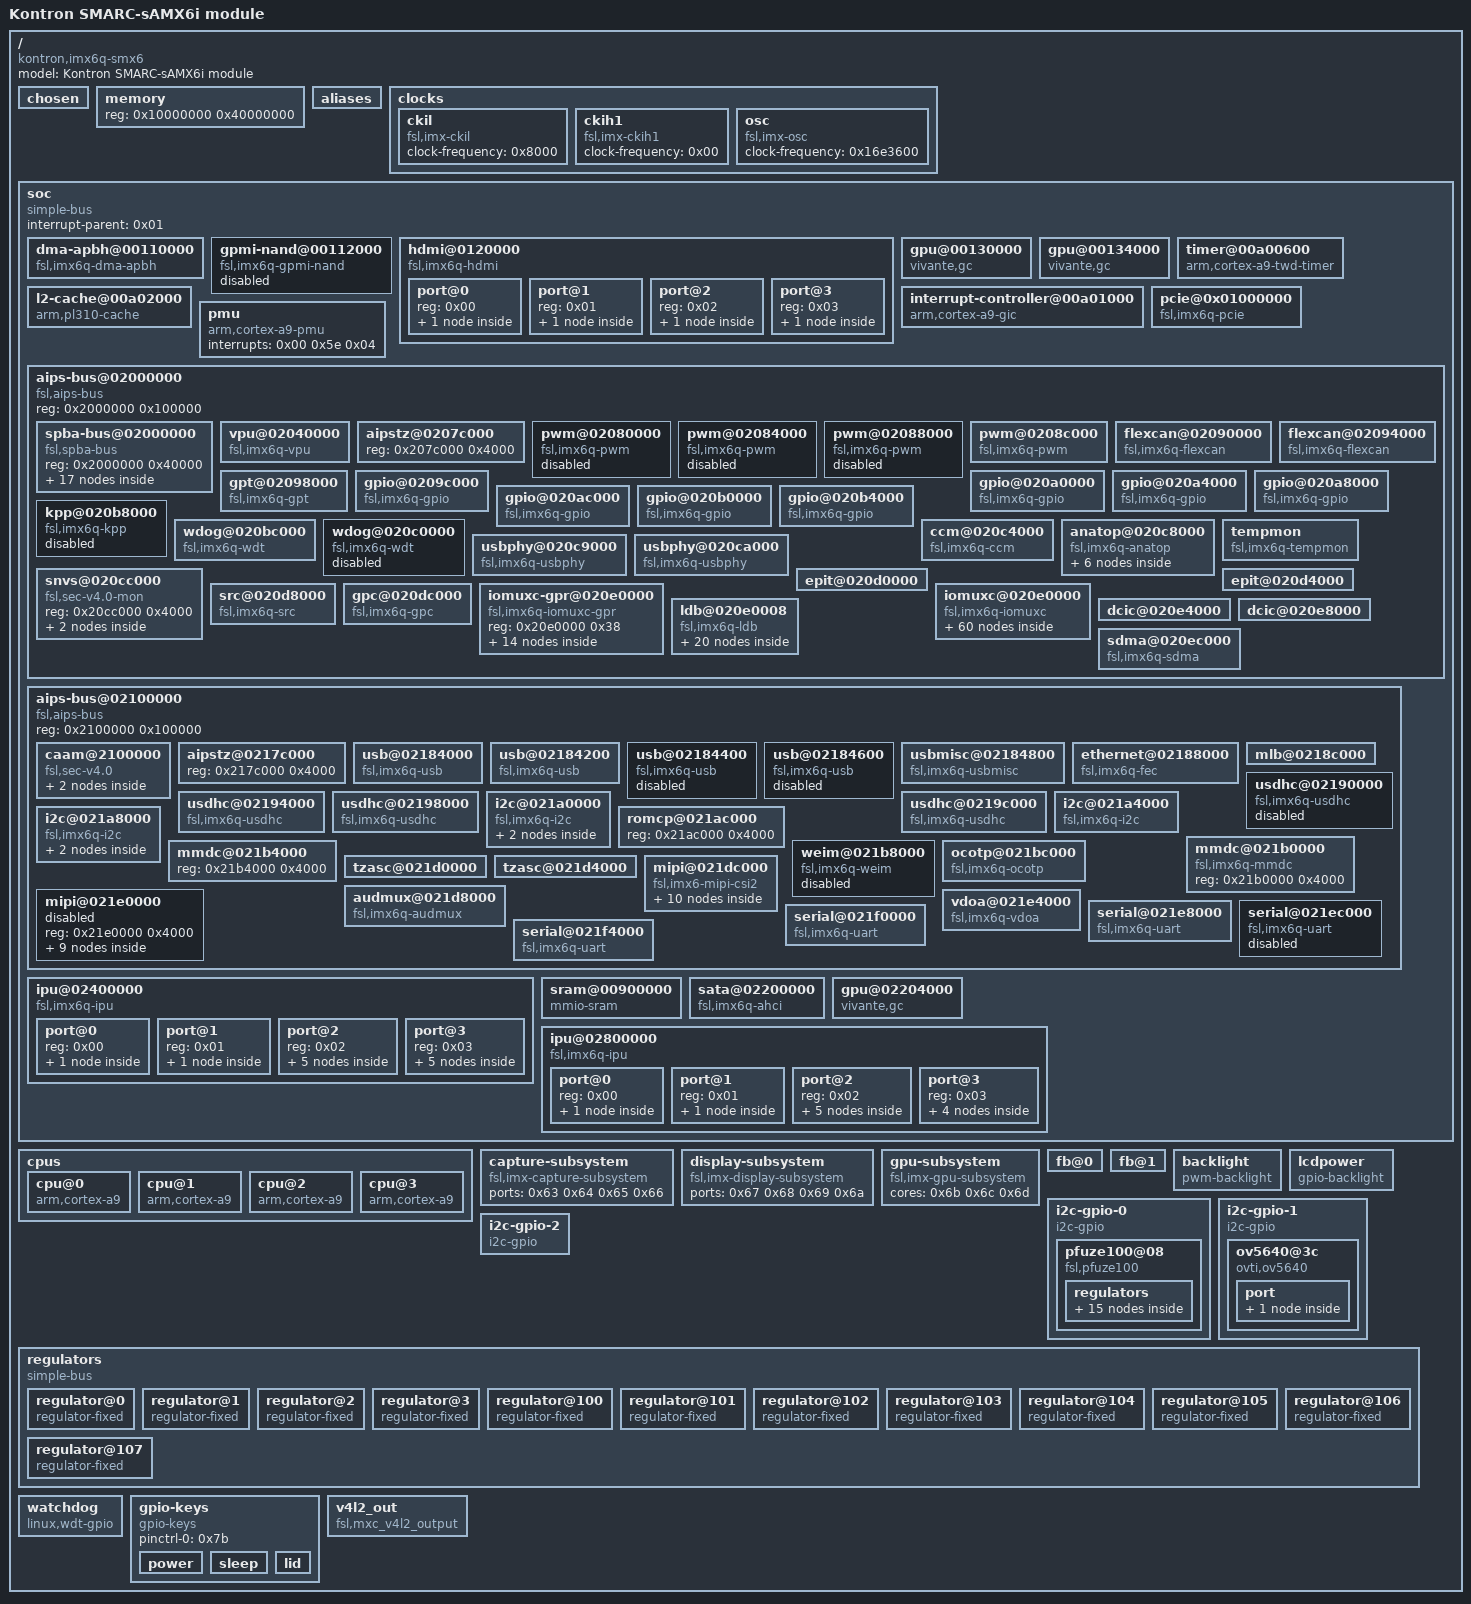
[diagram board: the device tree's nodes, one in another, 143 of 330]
/dts-v1/;

/ {
	#address-cells = <0x01>;
	#size-cells = <0x01>;
	model = "Kontron SMARC-sAMX6i module";
	compatible = "kontron,imx6q-smx6\0fsl,imx6q";

	chosen {
	};

	memory {
		device_type = "memory";
		reg = <0x10000000 0x40000000>;
	};

	aliases {
		ethernet0 = "/soc/aips-bus@02100000/ethernet@02188000";
		can0 = "/soc/aips-bus@02000000/flexcan@02090000";
		can1 = "/soc/aips-bus@02000000/flexcan@02094000";
		gpio0 = "/soc/aips-bus@02000000/gpio@0209c000";
		gpio1 = "/soc/aips-bus@02000000/gpio@020a0000";
		gpio2 = "/soc/aips-bus@02000000/gpio@020a4000";
		gpio3 = "/soc/aips-bus@02000000/gpio@020a8000";
		gpio4 = "/soc/aips-bus@02000000/gpio@020ac000";
		gpio5 = "/soc/aips-bus@02000000/gpio@020b0000";
		gpio6 = "/soc/aips-bus@02000000/gpio@020b4000";
		i2c0 = "/soc/aips-bus@02100000/i2c@021a0000";
		i2c1 = "/soc/aips-bus@02100000/i2c@021a4000";
		i2c2 = "/soc/aips-bus@02100000/i2c@021a8000";
		ipu0 = "/soc/ipu@02400000";
		mmc0 = "/soc/aips-bus@02100000/usdhc@02190000";
		mmc1 = "/soc/aips-bus@02100000/usdhc@02194000";
		mmc2 = "/soc/aips-bus@02100000/usdhc@02198000";
		mmc3 = "/soc/aips-bus@02100000/usdhc@0219c000";
		serial0 = "/soc/aips-bus@02000000/spba-bus@02000000/serial@02020000";
		serial1 = "/soc/aips-bus@02100000/serial@021e8000";
		serial2 = "/soc/aips-bus@02100000/serial@021ec000";
		serial3 = "/soc/aips-bus@02100000/serial@021f0000";
		serial4 = "/soc/aips-bus@02100000/serial@021f4000";
		spi0 = "/soc/aips-bus@02000000/spba-bus@02000000/ecspi@02014000";
		spi1 = "/soc/aips-bus@02000000/spba-bus@02000000/ecspi@0200c000";
		spi2 = "/soc/aips-bus@02000000/spba-bus@02000000/ecspi@02010000";
		spi3 = "/soc/aips-bus@02000000/spba-bus@02000000/ecspi@02014000";
		usbphy0 = "/soc/aips-bus@02000000/usbphy@020c9000";
		usbphy1 = "/soc/aips-bus@02000000/usbphy@020ca000";
		ipu1 = "/soc/ipu@02800000";
		spi4 = "/soc/aips-bus@02000000/spba-bus@02000000/ecspi@02018000";
		i2c3 = "/i2c-gpio-0";
		i2c4 = "/i2c-gpio-1";
		i2c5 = "/i2c-gpio-2";
	};

	clocks {
		#address-cells = <0x01>;
		#size-cells = <0x00>;

		ckil {
			compatible = "fsl,imx-ckil\0fixed-clock";
			#clock-cells = <0x00>;
			clock-frequency = <0x8000>;
		};

		ckih1 {
			compatible = "fsl,imx-ckih1\0fixed-clock";
			#clock-cells = <0x00>;
			clock-frequency = <0x00>;
		};

		osc {
			compatible = "fsl,imx-osc\0fixed-clock";
			#clock-cells = <0x00>;
			clock-frequency = <0x16e3600>;
		};
	};

	soc {
		#address-cells = <0x01>;
		#size-cells = <0x01>;
		compatible = "simple-bus";
		interrupt-parent = <0x01>;
		ranges;

		dma-apbh@00110000 {
			compatible = "fsl,imx6q-dma-apbh\0fsl,imx28-dma-apbh";
			reg = <0x110000 0x2000>;
			interrupts = <0x00 0x0d 0x04 0x00 0x0d 0x04 0x00 0x0d 0x04 0x00 0x0d 0x04>;
			interrupt-names = "gpmi0\0gpmi1\0gpmi2\0gpmi3";
			#dma-cells = <0x01>;
			dma-channels = <0x04>;
			clocks = <0x02 0x6a>;
			linux,phandle = <0x03>;
			phandle = <0x03>;
		};

		gpmi-nand@00112000 {
			compatible = "fsl,imx6q-gpmi-nand";
			#address-cells = <0x01>;
			#size-cells = <0x01>;
			reg = <0x112000 0x2000 0x114000 0x2000>;
			reg-names = "gpmi-nand\0bch";
			interrupts = <0x00 0x0f 0x04>;
			interrupt-names = "bch";
			clocks = <0x02 0x98 0x02 0x99 0x02 0x97 0x02 0x96 0x02 0x95>;
			clock-names = "gpmi_io\0gpmi_apb\0gpmi_bch\0gpmi_bch_apb\0per1_bch";
			dmas = <0x03 0x00>;
			dma-names = "rx-tx";
			status = "disabled";
		};

		hdmi@0120000 {
			#address-cells = <0x01>;
			#size-cells = <0x00>;
			reg = <0x120000 0x9000>;
			interrupts = <0x00 0x73 0x04>;
			gpr = <0x04>;
			clocks = <0x02 0x7b 0x02 0x7c>;
			clock-names = "iahb\0isfr";
			status = "okay";
			compatible = "fsl,imx6q-hdmi";
			ddc-i2c-bus = <0x05>;
			ipu_id = <0x01>;
			disp_id = <0x00>;

			port@0 {
				reg = <0x00>;

				endpoint {
					remote-endpoint = <0x06>;
					linux,phandle = <0x4e>;
					phandle = <0x4e>;
				};
			};

			port@1 {
				reg = <0x01>;

				endpoint {
					remote-endpoint = <0x07>;
					linux,phandle = <0x52>;
					phandle = <0x52>;
				};
			};

			port@2 {
				reg = <0x02>;

				endpoint {
					remote-endpoint = <0x08>;
					linux,phandle = <0x58>;
					phandle = <0x58>;
				};
			};

			port@3 {
				reg = <0x03>;

				endpoint {
					remote-endpoint = <0x09>;
					linux,phandle = <0x5c>;
					phandle = <0x5c>;
				};
			};
		};

		gpu@00130000 {
			compatible = "vivante,gc";
			reg = <0x130000 0x4000>;
			interrupts = <0x00 0x09 0x04>;
			clocks = <0x02 0x1b 0x02 0x7a 0x02 0x4a>;
			clock-names = "bus\0core\0shader";
			power-domains = <0x01 0x01>;
			linux,phandle = <0x6c>;
			phandle = <0x6c>;
		};

		gpu@00134000 {
			compatible = "vivante,gc";
			reg = <0x134000 0x4000>;
			interrupts = <0x00 0x0a 0x04>;
			clocks = <0x02 0x1a 0x02 0x79>;
			clock-names = "bus\0core";
			power-domains = <0x01 0x01>;
			linux,phandle = <0x6b>;
			phandle = <0x6b>;
		};

		timer@00a00600 {
			compatible = "arm,cortex-a9-twd-timer";
			reg = <0xa00600 0x20>;
			interrupts = <0x01 0x0d 0xf01>;
			interrupt-parent = <0x0a>;
			clocks = <0x02 0x0f>;
		};

		interrupt-controller@00a01000 {
			compatible = "arm,cortex-a9-gic";
			#interrupt-cells = <0x03>;
			interrupt-controller;
			reg = <0xa01000 0x1000 0xa00100 0x100>;
			interrupt-parent = <0x0a>;
			linux,phandle = <0x0a>;
			phandle = <0x0a>;
		};

		l2-cache@00a02000 {
			compatible = "arm,pl310-cache";
			reg = <0xa02000 0x1000>;
			interrupts = <0x00 0x5c 0x04>;
			cache-unified;
			cache-level = <0x02>;
			arm,tag-latency = <0x04 0x02 0x03>;
			arm,data-latency = <0x04 0x02 0x03>;
			arm,shared-override;
			linux,phandle = <0x60>;
			phandle = <0x60>;
		};

		pcie@0x01000000 {
			compatible = "fsl,imx6q-pcie\0snps,dw-pcie";
			reg = <0x1ffc000 0x4000 0x1f00000 0x80000>;
			reg-names = "dbi\0config";
			#address-cells = <0x03>;
			#size-cells = <0x02>;
			device_type = "pci";
			ranges = <0x81000000 0x00 0x00 0x1f80000 0x00 0x10000 0x82000000 0x00 0x1000000 0x1000000 0x00 0xf00000>;
			num-lanes = <0x01>;
			interrupts = <0x00 0x78 0x04>;
			interrupt-names = "msi";
			#interrupt-cells = <0x01>;
			interrupt-map-mask = <0x00 0x00 0x00 0x07>;
			interrupt-map = <0x00 0x00 0x00 0x01 0x01 0x00 0x7b 0x04 0x00 0x00 0x00 0x02 0x01 0x00 0x7a 0x04 0x00 0x00 0x00 0x03 0x01 0x00 0x79 0x04 0x00 0x00 0x00 0x04 0x01 0x00 0x78 0x04>;
			clocks = <0x02 0x90 0x02 0xce 0x02 0xbd>;
			clock-names = "pcie\0pcie_bus\0pcie_phy";
			status = "okay";
			fsl,max-link-speed = <0x01>;
			wake-up-gpio = <0x0b 0x12 0x00>;
			reset-gpio = <0x0c 0x00 0x01 0x0d 0x0d 0x01 0x0d 0x0e 0x01 0x0d 0x0f 0x01>;
			pinctrl-names = "default";
			pinctrl-0 = <0x0e>;
		};

		pmu {
			compatible = "arm,cortex-a9-pmu";
			interrupts = <0x00 0x5e 0x04>;
		};

		aips-bus@02000000 {
			compatible = "fsl,aips-bus\0simple-bus";
			#address-cells = <0x01>;
			#size-cells = <0x01>;
			reg = <0x2000000 0x100000>;
			ranges;

			spba-bus@02000000 {
				compatible = "fsl,spba-bus\0simple-bus";
				#address-cells = <0x01>;
				#size-cells = <0x01>;
				reg = <0x2000000 0x40000>;
				ranges;

				spdif@02004000 {
					compatible = "fsl,imx35-spdif";
					reg = <0x2004000 0x4000>;
					interrupts = <0x00 0x34 0x04>;
					dmas = <0x0f 0x0e 0x12 0x00 0x0f 0x0f 0x12 0x00>;
					dma-names = "rx\0tx";
					clocks = <0x02 0xf4 0x02 0x03 0x02 0xc5 0x02 0x6b 0x02 0x00 0x02 0x76 0x02 0x3e 0x02 0x00 0x02 0x00 0x02 0x9c>;
					clock-names = "core\0rxtx0\0rxtx1\0rxtx2\0rxtx3\0rxtx4\0rxtx5\0rxtx6\0rxtx7\0spba";
					status = "disabled";
				};

				ecspi@02008000 {
					#address-cells = <0x01>;
					#size-cells = <0x00>;
					compatible = "fsl,imx6q-ecspi\0fsl,imx51-ecspi";
					reg = <0x2008000 0x4000>;
					interrupts = <0x00 0x1f 0x04>;
					clocks = <0x02 0x70 0x02 0x70>;
					clock-names = "ipg\0per";
					dmas = <0x0f 0x03 0x08 0x01 0x0f 0x04 0x08 0x02>;
					dma-names = "rx\0tx";
					status = "disabled";
				};

				ecspi@0200c000 {
					#address-cells = <0x01>;
					#size-cells = <0x00>;
					compatible = "fsl,imx6q-ecspi\0fsl,imx51-ecspi";
					reg = <0x200c000 0x4000>;
					interrupts = <0x00 0x20 0x04>;
					clocks = <0x02 0x71 0x02 0x71>;
					clock-names = "ipg\0per";
					dmas = <0x0f 0x05 0x08 0x01 0x0f 0x06 0x08 0x02>;
					dma-names = "rx\0tx";
					status = "okay";
					pinctrl-names = "default";
					pinctrl-0 = <0x10>;
					fsl,spi-num-chipselects = <0x02>;
					cs-gpios = <0x0c 0x1a 0x00 0x0c 0x1b 0x00>;
				};

				ecspi@02010000 {
					#address-cells = <0x01>;
					#size-cells = <0x00>;
					compatible = "fsl,imx6q-ecspi\0fsl,imx51-ecspi";
					reg = <0x2010000 0x4000>;
					interrupts = <0x00 0x21 0x04>;
					clocks = <0x02 0x72 0x02 0x72>;
					clock-names = "ipg\0per";
					dmas = <0x0f 0x07 0x08 0x01 0x0f 0x08 0x08 0x02>;
					dma-names = "rx\0tx";
					status = "disabled";
				};

				ecspi@02014000 {
					#address-cells = <0x01>;
					#size-cells = <0x00>;
					compatible = "fsl,imx6q-ecspi\0fsl,imx51-ecspi";
					reg = <0x2014000 0x4000>;
					interrupts = <0x00 0x22 0x04>;
					clocks = <0x02 0x73 0x02 0x73>;
					clock-names = "ipg\0per";
					dmas = <0x0f 0x09 0x08 0x01 0x0f 0x0a 0x08 0x02>;
					dma-names = "rx\0tx";
					status = "okay";
					pinctrl-names = "default";
					pinctrl-0 = <0x11>;
					fsl,spi-num-chipselects = <0x03>;
					cs-gpios = <0x0d 0x18 0x00 0x0d 0x1d 0x00 0x0d 0x19 0x00>;

					spi-nor@0 {
						#address-cells = <0x01>;
						#size-cells = <0x01>;
						compatible = "winbond,w25q16dw\0jedec,spi-nor";
						spi-max-frequency = <0x1312d00>;
						reg = <0x00>;

						partition@0 {
							label = "bootloader";
							reg = <0x00 0xc0000>;
							read-only;
						};

						partition@c0000 {
							label = "environment";
							reg = <0xc0000 0x10000>;
						};

						partition@d0000 {
							label = "user";
							reg = <0xd0000 0x00>;
						};
					};
				};

				serial@02020000 {
					compatible = "fsl,imx6q-uart\0fsl,imx21-uart";
					reg = <0x2020000 0x4000>;
					interrupts = <0x00 0x1a 0x04>;
					clocks = <0x02 0xa0 0x02 0xa1>;
					clock-names = "ipg\0per";
					dmas = <0x0f 0x19 0x04 0x00 0x0f 0x1a 0x04 0x00>;
					dma-names = "rx\0tx";
					status = "okay";
					pinctrl-names = "default";
					pinctrl-0 = <0x12>;
					fsl,uart-has-rtscts;
				};

				esai@02024000 {
					#sound-dai-cells = <0x00>;
					compatible = "fsl,imx35-esai";
					reg = <0x2024000 0x4000>;
					interrupts = <0x00 0x33 0x04>;
					clocks = <0x02 0xd0 0x02 0xd1 0x02 0x76 0x02 0xd0 0x02 0x9c>;
					clock-names = "core\0mem\0extal\0fsys\0spba";
					dmas = <0x0f 0x17 0x15 0x00 0x0f 0x18 0x15 0x00>;
					dma-names = "rx\0tx";
					status = "disabled";
				};

				ssi@02028000 {
					#sound-dai-cells = <0x00>;
					compatible = "fsl,imx6q-ssi\0fsl,imx51-ssi";
					reg = <0x2028000 0x4000>;
					interrupts = <0x00 0x2e 0x04>;
					clocks = <0x02 0xb2 0x02 0x9d>;
					clock-names = "ipg\0baud";
					dmas = <0x0f 0x25 0x01 0x00 0x0f 0x26 0x01 0x00>;
					dma-names = "rx\0tx";
					fsl,fifo-depth = <0x0f>;
					status = "okay";
					linux,phandle = <0x7c>;
					phandle = <0x7c>;
				};

				ssi@0202c000 {
					#sound-dai-cells = <0x00>;
					compatible = "fsl,imx6q-ssi\0fsl,imx51-ssi";
					reg = <0x202c000 0x4000>;
					interrupts = <0x00 0x2f 0x04>;
					clocks = <0x02 0xb3 0x02 0x9e>;
					clock-names = "ipg\0baud";
					dmas = <0x0f 0x29 0x01 0x00 0x0f 0x2a 0x01 0x00>;
					dma-names = "rx\0tx";
					fsl,fifo-depth = <0x0f>;
					status = "disabled";
				};

				ssi@02030000 {
					#sound-dai-cells = <0x00>;
					compatible = "fsl,imx6q-ssi\0fsl,imx51-ssi";
					reg = <0x2030000 0x4000>;
					interrupts = <0x00 0x30 0x04>;
					clocks = <0x02 0xb4 0x02 0x9f>;
					clock-names = "ipg\0baud";
					dmas = <0x0f 0x2d 0x01 0x00 0x0f 0x2e 0x01 0x00>;
					dma-names = "rx\0tx";
					fsl,fifo-depth = <0x0f>;
					status = "disabled";
				};

				asrc@02034000 {
					compatible = "fsl,imx53-asrc";
					reg = <0x2034000 0x4000>;
					interrupts = <0x00 0x32 0x04>;
					clocks = <0x02 0xd2 0x02 0xd3 0x02 0x00 0x02 0x00 0x02 0x00 0x02 0x00 0x02 0x00 0x02 0x00 0x02 0x00 0x02 0x00 0x02 0x00 0x02 0x00 0x02 0x00 0x02 0x00 0x02 0x00 0x02 0x6b 0x02 0x00 0x02 0x00 0x02 0x9c>;
					clock-names = "mem\0ipg\0asrck_0\0asrck_1\0asrck_2\0asrck_3\0asrck_4\0asrck_5\0asrck_6\0asrck_7\0asrck_8\0asrck_9\0asrck_a\0asrck_b\0asrck_c\0asrck_d\0asrck_e\0asrck_f\0spba";
					dmas = <0x0f 0x11 0x17 0x01 0x0f 0x12 0x17 0x01 0x0f 0x13 0x17 0x01 0x0f 0x14 0x17 0x01 0x0f 0x15 0x17 0x01 0x0f 0x16 0x17 0x01>;
					dma-names = "rxa\0rxb\0rxc\0txa\0txb\0txc";
					fsl,asrc-rate = <0xbb80>;
					fsl,asrc-width = <0x10>;
					status = "okay";
				};

				spba@0203c000 {
					reg = <0x203c000 0x4000>;
				};

				ecspi@02018000 {
					#address-cells = <0x01>;
					#size-cells = <0x00>;
					compatible = "fsl,imx6q-ecspi\0fsl,imx51-ecspi";
					reg = <0x2018000 0x4000>;
					interrupts = <0x00 0x23 0x04>;
					clocks = <0x02 0x74 0x02 0x74>;
					clock-names = "ipg\0per";
					dmas = <0x0f 0x0b 0x07 0x01 0x0f 0x0c 0x07 0x02>;
					dma-names = "rx\0tx";
					status = "disabled";
				};
			};

			vpu@02040000 {
				compatible = "fsl,imx6q-vpu\0cnm,coda960";
				reg = <0x2040000 0x3c000>;
				interrupts = <0x00 0x0c 0x04 0x00 0x03 0x04>;
				interrupt-names = "bit\0jpeg";
				clocks = <0x02 0xa8 0x02 0x8c>;
				clock-names = "per\0ahb";
				power-domains = <0x01 0x01>;
				resets = <0x13 0x01>;
				iram = <0x14>;
			};

			aipstz@0207c000 {
				reg = <0x207c000 0x4000>;
			};

			pwm@02080000 {
				#pwm-cells = <0x02>;
				compatible = "fsl,imx6q-pwm\0fsl,imx27-pwm";
				reg = <0x2080000 0x4000>;
				interrupts = <0x00 0x53 0x04>;
				clocks = <0x02 0x3e 0x02 0x91>;
				clock-names = "ipg\0per";
				status = "disabled";
			};

			pwm@02084000 {
				#pwm-cells = <0x02>;
				compatible = "fsl,imx6q-pwm\0fsl,imx27-pwm";
				reg = <0x2084000 0x4000>;
				interrupts = <0x00 0x54 0x04>;
				clocks = <0x02 0x3e 0x02 0x92>;
				clock-names = "ipg\0per";
				status = "disabled";
			};

			pwm@02088000 {
				#pwm-cells = <0x02>;
				compatible = "fsl,imx6q-pwm\0fsl,imx27-pwm";
				reg = <0x2088000 0x4000>;
				interrupts = <0x00 0x55 0x04>;
				clocks = <0x02 0x3e 0x02 0x93>;
				clock-names = "ipg\0per";
				status = "disabled";
			};

			pwm@0208c000 {
				#pwm-cells = <0x02>;
				compatible = "fsl,imx6q-pwm\0fsl,imx27-pwm";
				reg = <0x208c000 0x4000>;
				interrupts = <0x00 0x56 0x04>;
				clocks = <0x02 0x3e 0x02 0x94>;
				clock-names = "ipg\0per";
				status = "okay";
				pinctrl-names = "default";
				pinctrl-0 = <0x15>;
				linux,phandle = <0x6f>;
				phandle = <0x6f>;
			};

			flexcan@02090000 {
				compatible = "fsl,imx6q-flexcan";
				reg = <0x2090000 0x4000>;
				interrupts = <0x00 0x6e 0x04>;
				clocks = <0x02 0x6c 0x02 0x6d>;
				clock-names = "ipg\0per";
				status = "okay";
				pinctrl-names = "default";
				pinctrl-0 = <0x16>;
				xceiver-supply = <0x17>;
			};

			flexcan@02094000 {
				compatible = "fsl,imx6q-flexcan";
				reg = <0x2094000 0x4000>;
				interrupts = <0x00 0x6f 0x04>;
				clocks = <0x02 0x6e 0x02 0x6f>;
				clock-names = "ipg\0per";
				status = "okay";
				pinctrl-names = "default";
				pinctrl-0 = <0x18>;
				xceiver-supply = <0x19>;
			};

			gpt@02098000 {
				compatible = "fsl,imx6q-gpt\0fsl,imx31-gpt";
				reg = <0x2098000 0x4000>;
				interrupts = <0x00 0x37 0x04>;
				clocks = <0x02 0x77 0x02 0x78 0x02 0xed>;
				clock-names = "ipg\0per\0osc_per";
			};

			gpio@0209c000 {
				compatible = "fsl,imx6q-gpio\0fsl,imx35-gpio";
				reg = <0x209c000 0x4000>;
				interrupts = <0x00 0x42 0x04 0x00 0x43 0x04>;
				gpio-controller;
				#gpio-cells = <0x02>;
				interrupt-controller;
				#interrupt-cells = <0x02>;
				gpio-ranges = <0x1a 0x00 0x88 0x02 0x1a 0x02 0x8d 0x01 0x1a 0x03 0x8b 0x01 0x1a 0x04 0x8e 0x02 0x1a 0x06 0x8c 0x01 0x1a 0x07 0x90 0x02 0x1a 0x09 0x8a 0x01 0x1a 0x0a 0xd5 0x03 0x1a 0x0d 0x14 0x01 0x1a 0x0e 0x13 0x01 0x1a 0x0f 0x15 0x01 0x1a 0x10 0xd0 0x01 0x1a 0x11 0xcf 0x01 0x1a 0x12 0xd2 0x03 0x1a 0x15 0xd1 0x01 0x1a 0x16 0x74 0x0a>;
				linux,phandle = <0x35>;
				phandle = <0x35>;
			};

			gpio@020a0000 {
				compatible = "fsl,imx6q-gpio\0fsl,imx35-gpio";
				reg = <0x20a0000 0x4000>;
				interrupts = <0x00 0x44 0x04 0x00 0x45 0x04>;
				gpio-controller;
				#gpio-cells = <0x02>;
				interrupt-controller;
				#interrupt-cells = <0x02>;
				gpio-ranges = <0x1a 0x00 0xbf 0x10 0x1a 0x10 0x37 0x0e 0x1a 0x1e 0x23 0x01 0x1a 0x1f 0x2c 0x01>;
				linux,phandle = <0x0c>;
				phandle = <0x0c>;
			};

			gpio@020a4000 {
				compatible = "fsl,imx6q-gpio\0fsl,imx35-gpio";
				reg = <0x20a4000 0x4000>;
				interrupts = <0x00 0x46 0x04 0x00 0x47 0x04>;
				gpio-controller;
				#gpio-cells = <0x02>;
				interrupt-controller;
				#interrupt-cells = <0x02>;
				gpio-ranges = <0x1a 0x00 0x45 0x10 0x1a 0x10 0x24 0x08 0x1a 0x18 0x2d 0x08>;
				linux,phandle = <0x0d>;
				phandle = <0x0d>;
			};

			gpio@020a8000 {
				compatible = "fsl,imx6q-gpio\0fsl,imx35-gpio";
				reg = <0x20a8000 0x4000>;
				interrupts = <0x00 0x48 0x04 0x00 0x49 0x04>;
				gpio-controller;
				#gpio-cells = <0x02>;
				interrupt-controller;
				#interrupt-cells = <0x02>;
				gpio-ranges = <0x1a 0x05 0x95 0x01 0x1a 0x06 0x7e 0x0a 0x1a 0x10 0x57 0x10>;
				linux,phandle = <0x76>;
				phandle = <0x76>;
			};

			gpio@020ac000 {
				compatible = "fsl,imx6q-gpio\0fsl,imx35-gpio";
				reg = <0x20ac000 0x4000>;
				interrupts = <0x00 0x4a 0x04 0x00 0x4b 0x04>;
				gpio-controller;
				#gpio-cells = <0x02>;
				interrupt-controller;
				#interrupt-cells = <0x02>;
				gpio-ranges = <0x1a 0x00 0x55 0x01 0x1a 0x02 0x22 0x01 0x1a 0x04 0x35 0x01 0x1a 0x05 0x67 0x0d 0x1a 0x12 0x96 0x0e>;
				linux,phandle = <0x7a>;
				phandle = <0x7a>;
			};

			gpio@020b0000 {
				compatible = "fsl,imx6q-gpio\0fsl,imx35-gpio";
				reg = <0x20b0000 0x4000>;
				interrupts = <0x00 0x4c 0x04 0x00 0x4d 0x04>;
				gpio-controller;
				#gpio-cells = <0x02>;
				interrupt-controller;
				#interrupt-cells = <0x02>;
				gpio-ranges = <0x1a 0x00 0xa4 0x06 0x1a 0x06 0x36 0x01 0x1a 0x07 0xb5 0x05 0x1a 0x0e 0xba 0x03 0x1a 0x11 0xaa 0x02 0x1a 0x13 0x16 0x0c 0x1a 0x1f 0x56 0x01>;
				linux,phandle = <0x0b>;
				phandle = <0x0b>;
			};

			gpio@020b4000 {
				compatible = "fsl,imx6q-gpio\0fsl,imx35-gpio";
				reg = <0x20b4000 0x4000>;
				interrupts = <0x00 0x4e 0x04 0x00 0x4f 0x04>;
				gpio-controller;
				#gpio-cells = <0x02>;
				interrupt-controller;
				#interrupt-cells = <0x02>;
				gpio-ranges = <0x1a 0x00 0xac 0x09 0x1a 0x09 0xbd 0x02 0x1a 0x0b 0x92 0x03>;
				linux,phandle = <0x74>;
				phandle = <0x74>;
			};

			kpp@020b8000 {
				compatible = "fsl,imx6q-kpp\0fsl,imx21-kpp";
				reg = <0x20b8000 0x4000>;
				interrupts = <0x00 0x52 0x04>;
				clocks = <0x02 0x3e>;
				status = "disabled";
			};

			wdog@020bc000 {
				compatible = "fsl,imx6q-wdt\0fsl,imx21-wdt";
				reg = <0x20bc000 0x4000>;
				interrupts = <0x00 0x50 0x04>;
				clocks = <0x02 0x00>;
			};

			wdog@020c0000 {
				compatible = "fsl,imx6q-wdt\0fsl,imx21-wdt";
				reg = <0x20c0000 0x4000>;
				interrupts = <0x00 0x51 0x04>;
				clocks = <0x02 0x00>;
				status = "disabled";
			};

			ccm@020c4000 {
				compatible = "fsl,imx6q-ccm";
				reg = <0x20c4000 0x4000>;
				interrupts = <0x00 0x57 0x04 0x00 0x58 0x04>;
				#clock-cells = <0x01>;
				linux,phandle = <0x02>;
				phandle = <0x02>;
			};

			anatop@020c8000 {
				compatible = "fsl,imx6q-anatop\0syscon\0simple-bus";
				reg = <0x20c8000 0x1000>;
				interrupts = <0x00 0x31 0x04 0x00 0x36 0x04 0x00 0x7f 0x04>;
				linux,phandle = <0x1b>;
				phandle = <0x1b>;

				regulator-1p1 {
					compatible = "fsl,anatop-regulator";
					regulator-name = "vdd1p1";
					regulator-min-microvolt = "\0\f5";
					regulator-max-microvolt = <0x14fb18>;
					regulator-always-on;
					anatop-reg-offset = <0x110>;
					anatop-vol-bit-shift = <0x08>;
					anatop-vol-bit-width = <0x05>;
					anatop-min-bit-val = <0x04>;
					anatop-min-voltage = "\0\f5";
					anatop-max-voltage = <0x14fb18>;
				};

				regulator-3p0 {
					compatible = "fsl,anatop-regulator";
					regulator-name = "vdd3p0";
					regulator-min-microvolt = <0x2ab980>;
					regulator-max-microvolt = <0x3010b0>;
					regulator-always-on;
					anatop-reg-offset = <0x120>;
					anatop-vol-bit-shift = <0x08>;
					anatop-vol-bit-width = <0x05>;
					anatop-min-bit-val = <0x00>;
					anatop-min-voltage = <0x280de8>;
					anatop-max-voltage = <0x33e140>;
				};

				regulator-2p5 {
					compatible = "fsl,anatop-regulator";
					regulator-name = "vdd2p5";
					regulator-min-microvolt = <0x1e8480>;
					regulator-max-microvolt = <0x29f630>;
					regulator-always-on;
					anatop-reg-offset = <0x130>;
					anatop-vol-bit-shift = <0x08>;
					anatop-vol-bit-width = <0x05>;
					anatop-min-bit-val = <0x00>;
					anatop-min-voltage = <0x1e8480>;
					anatop-max-voltage = <0x29f630>;
				};

				regulator-vddcore {
					compatible = "fsl,anatop-regulator";
					regulator-name = "vddarm";
					regulator-min-microvolt = <0xb1008>;
					regulator-max-microvolt = <0x162010>;
					regulator-always-on;
					anatop-reg-offset = <0x140>;
					anatop-vol-bit-shift = <0x00>;
					anatop-vol-bit-width = <0x05>;
					anatop-delay-reg-offset = <0x170>;
					anatop-delay-bit-shift = <0x18>;
					anatop-delay-bit-width = <0x02>;
					anatop-min-bit-val = <0x01>;
					anatop-min-voltage = <0xb1008>;
					anatop-max-voltage = <0x162010>;
					linux,phandle = <0x61>;
					phandle = <0x61>;
				};

				regulator-vddpu {
					compatible = "fsl,anatop-regulator";
					regulator-name = "vddpu";
					regulator-min-microvolt = <0xb1008>;
					regulator-max-microvolt = <0x162010>;
					regulator-enable-ramp-delay = <0x96>;
					anatop-reg-offset = <0x140>;
					anatop-vol-bit-shift = <0x09>;
					anatop-vol-bit-width = <0x05>;
					anatop-delay-reg-offset = <0x170>;
					anatop-delay-bit-shift = <0x1a>;
					anatop-delay-bit-width = <0x02>;
					anatop-min-bit-val = <0x01>;
					anatop-min-voltage = <0xb1008>;
					anatop-max-voltage = <0x162010>;
					linux,phandle = <0x1e>;
					phandle = <0x1e>;
				};

				regulator-vddsoc {
					compatible = "fsl,anatop-regulator";
					regulator-name = "vddsoc";
					regulator-min-microvolt = <0xb1008>;
					regulator-max-microvolt = <0x162010>;
					regulator-always-on;
					anatop-reg-offset = <0x140>;
					anatop-vol-bit-shift = <0x12>;
					anatop-vol-bit-width = <0x05>;
					anatop-delay-reg-offset = <0x170>;
					anatop-delay-bit-shift = <0x1c>;
					anatop-delay-bit-width = <0x02>;
					anatop-min-bit-val = <0x01>;
					anatop-min-voltage = <0xb1008>;
					anatop-max-voltage = <0x162010>;
					linux,phandle = <0x62>;
					phandle = <0x62>;
				};
			};

			tempmon {
				compatible = "fsl,imx6q-tempmon";
				interrupts = <0x00 0x31 0x04>;
				fsl,tempmon = <0x1b>;
				fsl,tempmon-data = <0x1c>;
				clocks = <0x02 0xac>;
			};

			usbphy@020c9000 {
				compatible = "fsl,imx6q-usbphy\0fsl,imx23-usbphy";
				reg = <0x20c9000 0x1000>;
				interrupts = <0x00 0x2c 0x04>;
				clocks = <0x02 0xb6>;
				fsl,anatop = <0x1b>;
				linux,phandle = <0x2d>;
				phandle = <0x2d>;
			};

			usbphy@020ca000 {
				compatible = "fsl,imx6q-usbphy\0fsl,imx23-usbphy";
				reg = <0x20ca000 0x1000>;
				interrupts = <0x00 0x2d 0x04>;
				clocks = <0x02 0xb7>;
				fsl,anatop = <0x1b>;
				linux,phandle = <0x31>;
				phandle = <0x31>;
			};

			snvs@020cc000 {
				compatible = "fsl,sec-v4.0-mon\0syscon\0simple-mfd";
				reg = <0x20cc000 0x4000>;
				linux,phandle = <0x1d>;
				phandle = <0x1d>;

				snvs-rtc-lp {
					compatible = "fsl,sec-v4.0-mon-rtc-lp";
					regmap = <0x1d>;
					offset = <0x34>;
					interrupts = <0x00 0x13 0x04 0x00 0x14 0x04>;
				};

				snvs-poweroff {
					compatible = "syscon-poweroff";
					regmap = <0x1d>;
					offset = <0x38>;
					mask = <0x60>;
					status = "okay";
				};
			};

			epit@020d0000 {
				reg = <0x20d0000 0x4000>;
				interrupts = <0x00 0x38 0x04>;
			};

			epit@020d4000 {
				reg = <0x20d4000 0x4000>;
				interrupts = <0x00 0x39 0x04>;
			};

			src@020d8000 {
				compatible = "fsl,imx6q-src\0fsl,imx51-src";
				reg = <0x20d8000 0x4000>;
				interrupts = <0x00 0x5b 0x04 0x00 0x60 0x04>;
				#reset-cells = <0x01>;
				linux,phandle = <0x13>;
				phandle = <0x13>;
			};

			gpc@020dc000 {
				compatible = "fsl,imx6q-gpc";
				reg = <0x20dc000 0x4000>;
				interrupt-controller;
				#interrupt-cells = <0x03>;
				interrupts = <0x00 0x59 0x04 0x00 0x5a 0x04>;
				interrupt-parent = <0x0a>;
				pu-supply = <0x1e>;
				clocks = <0x02 0x7a 0x02 0x4a 0x02 0x79 0x02 0x1a 0x02 0x8f 0x02 0xa8>;
				#power-domain-cells = <0x01>;
				linux,phandle = <0x01>;
				phandle = <0x01>;
			};

			iomuxc-gpr@020e0000 {
				compatible = "fsl,imx6q-iomuxc-gpr\0syscon\0simple-mfd";
				reg = <0x20e0000 0x38>;
				#address-cells = <0x01>;
				#size-cells = <0x00>;
				linux,phandle = <0x04>;
				phandle = <0x04>;

				ipu1_csi0_mux@4 {
					compatible = "video-multiplexer";
					reg = <0x04>;
					bit-mask = <0x01>;
					bit-shift = <0x13>;
					#address-cells = <0x01>;
					#size-cells = <0x00>;
					status = "okay";

					port@0 {
						reg = <0x00>;

						endpoint {
							remote-endpoint = <0x1f>;
							linux,phandle = <0x40>;
							phandle = <0x40>;
						};
					};

					port@1 {
						reg = <0x01>;

						endpoint {
						};
					};

					port@2 {
						reg = <0x02>;

						endpoint {
							remote-endpoint = <0x20>;
							linux,phandle = <0x4c>;
							phandle = <0x4c>;
						};
					};
				};

				ipu2_csi1_mux@4 {
					compatible = "video-multiplexer";
					reg = <0x04>;
					bit-mask = <0x01>;
					bit-shift = <0x14>;
					#address-cells = <0x01>;
					#size-cells = <0x00>;
					status = "okay";

					port@0 {
						reg = <0x00>;

						endpoint {
							remote-endpoint = <0x21>;
							linux,phandle = <0x43>;
							phandle = <0x43>;
						};
					};

					port@1 {
						reg = <0x01>;

						endpoint {
						};
					};

					port@2 {
						reg = <0x02>;

						endpoint {
							remote-endpoint = <0x22>;
							linux,phandle = <0x57>;
							phandle = <0x57>;
						};
					};
				};
			};

			iomuxc@020e0000 {
				compatible = "fsl,imx6q-iomuxc";
				reg = <0x20e0000 0x4000>;
				pinctrl-names = "default";
				pinctrl-0 = <0x23>;
				linux,phandle = <0x1a>;
				phandle = <0x1a>;

				hog {

					hoggrp-smx6 {
						fsl,pins = <0x114 0x428 0x00 0x05 0x00 0x4000b0b1 0x118 0x42c 0x00 0x05 0x00 0x4000b0b1 0x11c 0x430 0x00 0x05 0x00 0x4000b0b1 0x120 0x434 0x00 0x05 0x00 0x4000b0b1 0x124 0x438 0x00 0x05 0x00 0x4000b0b1 0x128 0x43c 0x00 0x05 0x00 0x4000b0b1 0x12c 0x440 0x00 0x05 0x00 0x4000b0b1 0x130 0x444 0x00 0x05 0x00 0x4000b0b1 0x134 0x448 0x00 0x05 0x00 0x4000b0b1 0x138 0x44c 0x00 0x05 0x00 0x4000b0b1 0x13c 0x450 0x00 0x05 0x00 0x4000b0b1 0x140 0x454 0x00 0x05 0x00 0x4000b0b1 0x2ec 0x6d4 0x00 0x04 0x00 0x80000000 0x25c 0x62c 0x00 0x03 0x00 0x80000000>;
						linux,phandle = <0x23>;
						phandle = <0x23>;
					};
				};

				uart1 {

					uart1grp-smx6 {
						fsl,pins = <0x284 0x654 0x920 0x03 0x01 0x1b0b1 0x280 0x650 0x00 0x03 0x00 0x1b0b1 0xa0 0x3b4 0x91c 0x04 0x01 0x1b0b1 0x9c 0x3b0 0x00 0x04 0x00 0x1b0b1>;
						linux,phandle = <0x12>;
						phandle = <0x12>;
					};
				};

				uart2 {

					uart2grp-smx6 {
						fsl,pins = <0xc0 0x3d4 0x928 0x04 0x01 0x1b0b1 0xbc 0x3d0 0x00 0x04 0x00 0x1b0b1>;
						linux,phandle = <0x49>;
						phandle = <0x49>;
					};
				};

				uart4 {

					uart4grp-smx6 {
						fsl,pins = <0x28c 0x65c 0x938 0x03 0x03 0x1b0b1 0x288 0x658 0x00 0x03 0x00 0x1b0b1 0x298 0x668 0x934 0x03 0x00 0x1b0b1 0x29c 0x66c 0x00 0x03 0x00 0x1b0b1>;
						linux,phandle = <0x4a>;
						phandle = <0x4a>;
					};
				};

				uart5 {

					uart5grp-smx6 {
						fsl,pins = <0x294 0x664 0x940 0x03 0x03 0x1b0b1 0x290 0x660 0x00 0x03 0x00 0x1b0b1>;
						linux,phandle = <0x4b>;
						phandle = <0x4b>;
					};
				};

				fec {

					fecgrp-smx6 {
						fsl,pins = <0x1d0 0x4e4 0x840 0x01 0x00 0x1b0b0 0x1f4 0x508 0x00 0x01 0x00 0x1b0b0 0x58 0x36c 0x00 0x01 0x00 0x1b0b0 0x5c 0x370 0x00 0x01 0x00 0x1b0b0 0x60 0x374 0x00 0x01 0x00 0x1b0b0 0x64 0x378 0x00 0x01 0x00 0x1b0b0 0x68 0x37c 0x00 0x01 0x00 0x1b0b0 0x74 0x388 0x00 0x01 0x00 0x1b0b0 0x1d4 0x4e8 0x00 0x01 0x00 0x1b0b0 0x84 0x398 0x844 0x01 0x00 0x1b0b0 0x70 0x384 0x848 0x01 0x00 0x1b0b0 0x78 0x38c 0x84c 0x01 0x00 0x1b0b0 0x7c 0x390 0x850 0x01 0x00 0x1b0b0 0x80 0x394 0x854 0x01 0x00 0x1b0b0 0x6c 0x380 0x858 0x01 0x00 0x1b0b0>;
						linux,phandle = <0x33>;
						phandle = <0x33>;
					};
				};

				ecspi2 {

					ecspi2grp-smx6 {
						fsl,pins = <0xf8 0x40c 0x810 0x02 0x00 0x80000000 0xfc 0x410 0x818 0x02 0x00 0x80000000 0x100 0x414 0x814 0x02 0x00 0x80000000 0x104 0x418 0x00 0x05 0x00 0x80000000 0x108 0x41c 0x00 0x05 0x00 0x80000000>;
						linux,phandle = <0x10>;
						phandle = <0x10>;
					};
				};

				ecspi4 {

					ecspi4grp-smx6 {
						fsl,pins = <0xa4 0x3b8 0x00 0x01 0x00 0x80000000 0xc4 0x3d8 0x00 0x02 0x00 0x80000000 0xa8 0x3bc 0x00 0x01 0x00 0x80000000 0xb4 0x3c8 0x00 0x05 0x00 0x80000000 0xc8 0x3dc 0x00 0x05 0x00 0x80000000 0xb8 0x3cc 0x00 0x05 0x00 0x80000000>;
						linux,phandle = <0x11>;
						phandle = <0x11>;
					};
				};

				usbotg {

					usbothgrp-smx6 {
						fsl,pins = <0x224 0x5f4 0x04 0x03 0xff0d0101 0x1f8b0 0x258 0x628 0x00 0x05 0x00 0x80000000>;
						linux,phandle = <0x2f>;
						phandle = <0x2f>;
					};
				};

				usdhc2 {

					usdhc2grp-smx6 {
						fsl,pins = <0x354 0x73c 0x00 0x00 0x00 0x17059 0x358 0x740 0x00 0x00 0x00 0x17059 0x54 0x368 0x00 0x00 0x00 0x17059 0x4c 0x360 0x00 0x00 0x00 0x17059 0x50 0x364 0x00 0x00 0x00 0x17059 0x35c 0x744 0x00 0x00 0x00 0x17059 0x30c 0x6f4 0x00 0x01 0x00 0x17059 0x310 0x6f8 0x00 0x01 0x00 0x17059 0x314 0x6fc 0x00 0x01 0x00 0x17059 0x318 0x700 0x00 0x01 0x00 0x17059 0x238 0x608 0x00 0x05 0x00 0x80000000>;
						linux,phandle = <0x34>;
						phandle = <0x34>;
					};
				};

				usdhc3 {

					usdhc3grp-smx6 {
						fsl,pins = <0x2bc 0x6a4 0x00 0x00 0x00 0x17059 0x2b8 0x6a0 0x00 0x00 0x00 0x17059 0x2c0 0x6a8 0x00 0x00 0x00 0x17059 0x2c4 0x6ac 0x00 0x00 0x00 0x17059 0x2c8 0x6b0 0x00 0x00 0x00 0x17059 0x2cc 0x6b4 0x00 0x00 0x00 0x17059 0x2e8 0x6d0 0x00 0x05 0x00 0x80000000 0x1e0 0x4f4 0x00 0x05 0x00 0x80000000 0x1ec 0x500 0x00 0x05 0x00 0x80000000>;
						linux,phandle = <0x36>;
						phandle = <0x36>;
					};
				};

				usdhc4 {

					usdhc4grp-smx6 {
						fsl,pins = <0x2f8 0x6e0 0x00 0x00 0x00 0x17059 0x2f4 0x6dc 0x00 0x00 0x00 0x17059 0x31c 0x704 0x00 0x01 0x00 0x17059 0x320 0x708 0x00 0x01 0x00 0x17059 0x324 0x70c 0x00 0x01 0x00 0x17059 0x328 0x710 0x00 0x01 0x00 0x17059 0x32c 0x714 0x00 0x01 0x00 0x17059 0x330 0x718 0x00 0x01 0x00 0x17059 0x334 0x71c 0x00 0x01 0x00 0x17059 0x338 0x720 0x00 0x01 0x00 0x17059>;
						linux,phandle = <0x38>;
						phandle = <0x38>;
					};
				};

				lcd {

					lcdgrp-smx6 {
						fsl,pins = <0x170 0x484 0x00 0x00 0x00 0x100f1 0x174 0x488 0x00 0x00 0x00 0x100f1 0x178 0x48c 0x00 0x00 0x00 0x100f1 0x17c 0x490 0x00 0x00 0x00 0x100f1 0x180 0x494 0x00 0x00 0x00 0x100f1 0x184 0x498 0x00 0x00 0x00 0x100f1 0x188 0x49c 0x00 0x00 0x00 0x100f1 0x18c 0x4a0 0x00 0x00 0x00 0x100f1 0x190 0x4a4 0x00 0x00 0x00 0x100f1 0x194 0x4a8 0x00 0x00 0x00 0x100f1 0x198 0x4ac 0x00 0x00 0x00 0x100f1 0x19c 0x4b0 0x00 0x00 0x00 0x100f1 0x1a0 0x4b4 0x00 0x00 0x00 0x100f1 0x1a4 0x4b8 0x00 0x00 0x00 0x100f1 0x1a8 0x4bc 0x00 0x00 0x00 0x100f1 0x1ac 0x4c0 0x00 0x00 0x00 0x100f1 0x1b0 0x4c4 0x00 0x00 0x00 0x100f1 0x1b4 0x4c8 0x00 0x00 0x00 0x100f1 0x1b8 0x4cc 0x00 0x00 0x00 0x100f1 0x1bc 0x4d0 0x00 0x00 0x00 0x100f1 0x1c0 0x4d4 0x00 0x00 0x00 0x100f1 0x1c4 0x4d8 0x00 0x00 0x00 0x100f1 0x1c8 0x4dc 0x00 0x00 0x00 0x100f1 0x1cc 0x4e0 0x00 0x00 0x00 0x100f1 0x15c 0x470 0x00 0x00 0x00 0x100f1 0x160 0x474 0x00 0x00 0x00 0x100f1 0x164 0x478 0x00 0x00 0x00 0x100f1 0x168 0x47c 0x00 0x00 0x00 0x100f1>;
					};
				};

				backlight {

					backlightgrp-smx6 {
						fsl,pins = <0x340 0x728 0x00 0x05 0x00 0x80000000>;
						linux,phandle = <0x6e>;
						phandle = <0x6e>;
					};
				};

				lcdpower {

					lcdpowergrp-smx6 {
						fsl,pins = <0x33c 0x724 0x00 0x05 0x00 0x80000000>;
						linux,phandle = <0x72>;
						phandle = <0x72>;
					};
				};

				pwm4 {

					pwm4grp-smx6 {
						fsl,pins = <0x348 0x730 0x00 0x02 0x00 0x80000000>;
						linux,phandle = <0x15>;
						phandle = <0x15>;
					};
				};

				i2c1 {

					i2c1grp-smx6 {
						fsl,pins = <0x278 0x648 0x89c 0x04 0x01 0x4001b8b1 0x27c 0x64c 0x898 0x04 0x01 0x4001b8b1>;
						linux,phandle = <0x39>;
						phandle = <0x39>;
					};
				};

				i2c2 {

					i2c2grp-smx6 {
						fsl,pins = <0x210 0x5e0 0x8a0 0x04 0x01 0x4001b8b1 0x214 0x5e4 0x8a4 0x04 0x01 0x4001b8b1>;
						linux,phandle = <0x3c>;
						phandle = <0x3c>;
					};
				};

				i2c3 {

					i2c3grp-smx6 {
						fsl,pins = <0x23c 0x60c 0x8a8 0x06 0x02 0x4001b8b1 0x248 0x618 0x8ac 0x06 0x02 0x4001b8b1>;
						linux,phandle = <0x3d>;
						phandle = <0x3d>;
					};
				};

				i2c-gpio-0 {

					i2c-gpio-0grp-smx6 {
						fsl,pins = <0x1f0 0x504 0x00 0x05 0x00 0x80000000 0x1e8 0x4fc 0x00 0x05 0x00 0x80000000>;
						linux,phandle = <0x73>;
						phandle = <0x73>;
					};
				};

				i2c-gpio-1 {

					i2c-gpio-1grp-smx6 {
						fsl,pins = <0x230 0x600 0x00 0x05 0x00 0x80000000 0x208 0x5d8 0x00 0x05 0x00 0x80000000>;
						linux,phandle = <0x75>;
						phandle = <0x75>;
					};
				};

				i2c-gpio-2 {

					i2c-gpio-2grp-smx6 {
						fsl,pins = <0x34c 0x734 0x00 0x05 0x00 0x80000000 0x344 0x72c 0x00 0x05 0x00 0x80000000>;
						linux,phandle = <0x78>;
						phandle = <0x78>;
					};
				};

				pcie {

					pciegrp-smx6 {
						fsl,pins = <0x148 0x45c 0x00 0x05 0x00 0x80000000 0x2ac 0x694 0x00 0x05 0x00 0x80000000>;
						linux,phandle = <0x0e>;
						phandle = <0x0e>;
					};
				};

				flexcan1 {

					flexcan1grp-smx6 {
						fsl,pins = <0x240 0x610 0x00 0x03 0x00 0x80000000 0x244 0x614 0x7e4 0x03 0x01 0x80000000>;
						linux,phandle = <0x16>;
						phandle = <0x16>;
					};
				};

				flexcan2 {

					flexcan2grp-smx6 {
						fsl,pins = <0x218 0x5e8 0x00 0x00 0x00 0x80000000 0x21c 0x5ec 0x7e8 0x00 0x00 0x80000000>;
						linux,phandle = <0x18>;
						phandle = <0x18>;
					};
				};

				keys {

					keysgrp-smx6 {
						fsl,pins = <0x2f0 0x6d8 0x00 0x05 0x00 0x80000000 0x2a8 0x690 0x00 0x05 0x00 0x80000000 0x154 0x468 0x00 0x05 0x00 0x80000000>;
						linux,phandle = <0x7b>;
						phandle = <0x7b>;
					};
				};

				hdmi_cec {

					hdmi_cecgrp-smx6 {
						fsl,pins = <0x88 0x39c 0x88c 0x06 0x00 0x1f8b0>;
					};
				};

				hdmi_video {

					hdmi_videogrp-smx6 {
						fsl,pins = <0x210 0x5e0 0x890 0x02 0x01 0x4001b8b1 0x214 0x5e4 0x894 0x02 0x01 0x4001b8b1>;
					};
				};

				wdog1 {

					wdoggrp-smx6 {
						fsl,pins = <0x228 0x5f8 0x00 0x01 0x00 0x80000000>;
					};
				};

				audmux {

					audmuxgrp-smx6 {
						fsl,pins = <0x268 0x638 0x00 0x04 0x00 0x80000000 0x26c 0x63c 0x00 0x04 0x00 0x80000000 0x270 0x640 0x00 0x04 0x00 0x80000000 0x274 0x644 0x00 0x04 0x00 0x80000000>;
						linux,phandle = <0x3f>;
						phandle = <0x3f>;
					};
				};
			};

			ldb@020e0008 {
				#address-cells = <0x01>;
				#size-cells = <0x00>;
				compatible = "fsl,imx6q-ldb\0fsl,imx53-ldb";
				gpr = <0x04>;
				status = "okay";
				clocks = <0x02 0x21 0x02 0x22 0x02 0x27 0x02 0x28 0x02 0x29 0x02 0x2a 0x02 0x87 0x02 0x88>;
				clock-names = "di0_pll\0di1_pll\0di0_sel\0di1_sel\0di2_sel\0di3_sel\0di0\0di1";

				lvds-channel@0 {
					#address-cells = <0x01>;
					#size-cells = <0x00>;
					reg = <0x00>;
					status = "okay";
					fsl,data-mapping = "spwg";
					fsl,data-width = <0x18>;
					crtc = "ipu1-di0";
					primary;

					port@0 {
						reg = <0x00>;

						endpoint {
							remote-endpoint = <0x24>;
							linux,phandle = <0x50>;
							phandle = <0x50>;
						};
					};

					port@1 {
						reg = <0x01>;

						endpoint {
							remote-endpoint = <0x25>;
							linux,phandle = <0x54>;
							phandle = <0x54>;
						};
					};

					port@2 {
						reg = <0x02>;

						endpoint {
							remote-endpoint = <0x26>;
							linux,phandle = <0x5a>;
							phandle = <0x5a>;
						};
					};

					port@3 {
						reg = <0x03>;

						endpoint {
							remote-endpoint = <0x27>;
							linux,phandle = <0x5e>;
							phandle = <0x5e>;
						};
					};

					display-timings {
						native-mode = <0x28>;

						panel {
							clock-frequency = <0x43b5fc0>;
							hactive = <0x500>;
							vactive = <0x320>;
							hback-porch = <0x50>;
							hfront-porch = <0x30>;
							vback-porch = <0x0f>;
							vfront-porch = <0x02>;
							hsync-len = <0x20>;
							vsync-len = <0x06>;
							linux,phandle = <0x28>;
							phandle = <0x28>;
						};
					};
				};

				lvds-channel@1 {
					#address-cells = <0x01>;
					#size-cells = <0x00>;
					reg = <0x01>;
					status = "disabled";

					port@0 {
						reg = <0x00>;

						endpoint {
							remote-endpoint = <0x29>;
							linux,phandle = <0x51>;
							phandle = <0x51>;
						};
					};

					port@1 {
						reg = <0x01>;

						endpoint {
							remote-endpoint = <0x2a>;
							linux,phandle = <0x55>;
							phandle = <0x55>;
						};
					};

					port@2 {
						reg = <0x02>;

						endpoint {
							remote-endpoint = <0x2b>;
							linux,phandle = <0x5b>;
							phandle = <0x5b>;
						};
					};

					port@3 {
						reg = <0x03>;

						endpoint {
							remote-endpoint = <0x2c>;
							linux,phandle = <0x5f>;
							phandle = <0x5f>;
						};
					};
				};
			};

			dcic@020e4000 {
				reg = <0x20e4000 0x4000>;
				interrupts = <0x00 0x7c 0x04>;
			};

			dcic@020e8000 {
				reg = <0x20e8000 0x4000>;
				interrupts = <0x00 0x7d 0x04>;
			};

			sdma@020ec000 {
				compatible = "fsl,imx6q-sdma\0fsl,imx35-sdma";
				reg = <0x20ec000 0x4000>;
				interrupts = <0x00 0x02 0x04>;
				clocks = <0x02 0x9b 0x02 0x9b>;
				clock-names = "ipg\0ahb";
				#dma-cells = <0x03>;
				fsl,sdma-ram-script-name = "imx/sdma/sdma-imx6q.bin";
				linux,phandle = <0x0f>;
				phandle = <0x0f>;
			};
		};

		aips-bus@02100000 {
			compatible = "fsl,aips-bus\0simple-bus";
			#address-cells = <0x01>;
			#size-cells = <0x01>;
			reg = <0x2100000 0x100000>;
			ranges;

			caam@2100000 {
				compatible = "fsl,sec-v4.0";
				fsl,sec-era = <0x04>;
				#address-cells = <0x01>;
				#size-cells = <0x01>;
				reg = <0x2100000 0x10000>;
				ranges = <0x00 0x2100000 0x10000>;
				clocks = <0x02 0xf1 0x02 0xf2 0x02 0xf3 0x02 0xc4>;
				clock-names = "mem\0aclk\0ipg\0emi_slow";

				jr0@1000 {
					compatible = "fsl,sec-v4.0-job-ring";
					reg = <0x1000 0x1000>;
					interrupts = <0x00 0x69 0x04>;
				};

				jr1@2000 {
					compatible = "fsl,sec-v4.0-job-ring";
					reg = <0x2000 0x1000>;
					interrupts = <0x00 0x6a 0x04>;
				};
			};

			aipstz@0217c000 {
				reg = <0x217c000 0x4000>;
			};

			usb@02184000 {
				compatible = "fsl,imx6q-usb\0fsl,imx27-usb";
				reg = <0x2184000 0x200>;
				interrupts = <0x00 0x2b 0x04>;
				clocks = <0x02 0xa2>;
				fsl,usbphy = <0x2d>;
				fsl,usbmisc = <0x2e 0x00>;
				ahb-burst-config = <0x00>;
				tx-burst-size-dword = <0x10>;
				rx-burst-size-dword = <0x10>;
				status = "okay";
				pinctrl-names = "default";
				pinctrl-0 = <0x2f>;
				vbus-supply = <0x30>;
			};

			usb@02184200 {
				compatible = "fsl,imx6q-usb\0fsl,imx27-usb";
				reg = <0x2184200 0x200>;
				interrupts = <0x00 0x28 0x04>;
				clocks = <0x02 0xa2>;
				fsl,usbphy = <0x31>;
				fsl,usbmisc = <0x2e 0x01>;
				dr_mode = "host";
				ahb-burst-config = <0x00>;
				tx-burst-size-dword = <0x10>;
				rx-burst-size-dword = <0x10>;
				status = "okay";
				vbus-supply = <0x32>;
			};

			usb@02184400 {
				compatible = "fsl,imx6q-usb\0fsl,imx27-usb";
				reg = <0x2184400 0x200>;
				interrupts = <0x00 0x29 0x04>;
				clocks = <0x02 0xa2>;
				fsl,usbmisc = <0x2e 0x02>;
				dr_mode = "host";
				ahb-burst-config = <0x00>;
				tx-burst-size-dword = <0x10>;
				rx-burst-size-dword = <0x10>;
				status = "disabled";
			};

			usb@02184600 {
				compatible = "fsl,imx6q-usb\0fsl,imx27-usb";
				reg = <0x2184600 0x200>;
				interrupts = <0x00 0x2a 0x04>;
				clocks = <0x02 0xa2>;
				fsl,usbmisc = <0x2e 0x03>;
				dr_mode = "host";
				ahb-burst-config = <0x00>;
				tx-burst-size-dword = <0x10>;
				rx-burst-size-dword = <0x10>;
				status = "disabled";
			};

			usbmisc@02184800 {
				#index-cells = <0x01>;
				compatible = "fsl,imx6q-usbmisc";
				reg = <0x2184800 0x200>;
				clocks = <0x02 0xa2>;
				linux,phandle = <0x2e>;
				phandle = <0x2e>;
			};

			ethernet@02188000 {
				compatible = "fsl,imx6q-fec";
				reg = <0x2188000 0x4000>;
				interrupts-extended = <0x01 0x00 0x76 0x04 0x01 0x00 0x77 0x04>;
				clocks = <0x02 0x75 0x02 0x75 0x02 0xbe>;
				clock-names = "ipg\0ahb\0ptp";
				status = "okay";
				pinctrl-names = "default";
				pinctrl-0 = <0x33>;
				phy-mode = "rgmii";
				phy-supply = <0x32>;
				fsl,magic-packet;
			};

			mlb@0218c000 {
				reg = <0x218c000 0x4000>;
				interrupts = <0x00 0x35 0x04 0x00 0x75 0x04 0x00 0x7e 0x04>;
			};

			usdhc@02190000 {
				compatible = "fsl,imx6q-usdhc";
				reg = <0x2190000 0x4000>;
				interrupts = <0x00 0x16 0x04>;
				clocks = <0x02 0xa3 0x02 0xa3 0x02 0xa3>;
				clock-names = "ipg\0ahb\0per";
				bus-width = <0x04>;
				status = "disabled";
			};

			usdhc@02194000 {
				compatible = "fsl,imx6q-usdhc";
				reg = <0x2194000 0x4000>;
				interrupts = <0x00 0x17 0x04>;
				clocks = <0x02 0xa4 0x02 0xa4 0x02 0xa4>;
				clock-names = "ipg\0ahb\0per";
				bus-width = <0x08>;
				status = "okay";
				pinctrl-names = "default";
				pinctrl-0 = <0x34>;
				cd-gpios = <0x35 0x04 0x01>;
				no-1-8-v;
			};

			usdhc@02198000 {
				compatible = "fsl,imx6q-usdhc";
				reg = <0x2198000 0x4000>;
				interrupts = <0x00 0x18 0x04>;
				clocks = <0x02 0xa5 0x02 0xa5 0x02 0xa5>;
				clock-names = "ipg\0ahb\0per";
				bus-width = <0x04>;
				status = "okay";
				pinctrl-names = "default";
				pinctrl-0 = <0x36>;
				cd-gpios = <0x0b 0x0e 0x01>;
				wp-gpios = <0x35 0x1a 0x00>;
				vmmc-supply = <0x37>;
				no-1-8-v;
			};

			usdhc@0219c000 {
				compatible = "fsl,imx6q-usdhc";
				reg = <0x219c000 0x4000>;
				interrupts = <0x00 0x19 0x04>;
				clocks = <0x02 0xa6 0x02 0xa6 0x02 0xa6>;
				clock-names = "ipg\0ahb\0per";
				bus-width = <0x08>;
				status = "okay";
				pinctrl-names = "default";
				pinctrl-0 = <0x38>;
				no-1-8-v;
				non-removable;
			};

			i2c@021a0000 {
				#address-cells = <0x01>;
				#size-cells = <0x00>;
				compatible = "fsl,imx6q-i2c\0fsl,imx21-i2c";
				reg = <0x21a0000 0x4000>;
				interrupts = <0x00 0x24 0x04>;
				clocks = <0x02 0x7d>;
				status = "okay";
				clock-frequency = <0x186a0>;
				pinctrl-names = "default";
				pinctrl-0 = <0x39>;

				wm8903@1b {
					compatible = "wlf,wm8903";
					reg = <0x1b>;
					clocks = <0x02 0xc8>;
					micdet-cfg = <0x00>;
					micdet-delay = <0x64>;
					linux,phandle = <0x7d>;
					phandle = <0x7d>;
				};

				lis3lv02d@1c {
					compatible = "st,lis3lv02d";
					reg = <0x1c>;
					st,click-single-x;
					st,click-single-y;
					st,click-single-z;
					st,click-thresh-x = <0x0a>;
					st,click-thresh-y = <0x0a>;
					st,click-thresh-z = <0x0a>;
					st,irq1-click;
					st,irq2-click;
					st,wakeup-x-lo;
					st,wakeup-x-hi;
					st,wakeup-y-lo;
					st,wakeup-y-hi;
					st,wakeup-z-lo;
					st,wakeup-z-hi;
					st,min-limit-x = <0x78>;
					st,min-limit-y = <0x78>;
					st,min-limit-z = <0x8c>;
					st,max-limit-x = <0x226>;
					st,max-limit-y = <0x226>;
					st,max-limit-z = <0x2ee>;
					Vdd-supply = <0x3a>;
					Vdd_IO-supply = <0x3b>;
				};
			};

			i2c@021a4000 {
				#address-cells = <0x01>;
				#size-cells = <0x00>;
				compatible = "fsl,imx6q-i2c\0fsl,imx21-i2c";
				reg = <0x21a4000 0x4000>;
				interrupts = <0x00 0x25 0x04>;
				clocks = <0x02 0x7e>;
				status = "okay";
				clock-frequency = <0x186a0>;
				pinctrl-names = "default";
				pinctrl-0 = <0x3c>;
				linux,phandle = <0x05>;
				phandle = <0x05>;
			};

			i2c@021a8000 {
				#address-cells = <0x01>;
				#size-cells = <0x00>;
				compatible = "fsl,imx6q-i2c\0fsl,imx21-i2c";
				reg = <0x21a8000 0x4000>;
				interrupts = <0x00 0x26 0x04>;
				clocks = <0x02 0x7f>;
				status = "okay";
				clock-frequency = <0x186a0>;
				pinctrl-names = "default";
				pinctrl-0 = <0x3d>;

				at24@50 {
					compatible = "at24,24c32";
					pagesize = <0x08>;
					reg = <0x50>;
				};

				tca9554@22 {
					compatible = "nxp,pca9554";
					reg = <0x22>;
					gpio-controller;
					#gpio-cells = <0x02>;
					vcc-supply = <0x3e>;
					linux,phandle = <0x79>;
					phandle = <0x79>;
				};
			};

			romcp@021ac000 {
				reg = <0x21ac000 0x4000>;
			};

			mmdc@021b0000 {
				compatible = "fsl,imx6q-mmdc";
				reg = <0x21b0000 0x4000>;
			};

			mmdc@021b4000 {
				reg = <0x21b4000 0x4000>;
			};

			weim@021b8000 {
				#address-cells = <0x02>;
				#size-cells = <0x01>;
				compatible = "fsl,imx6q-weim";
				reg = <0x21b8000 0x4000>;
				interrupts = <0x00 0x0e 0x04>;
				clocks = <0x02 0xc4>;
				fsl,weim-cs-gpr = <0x04>;
				status = "disabled";
			};

			ocotp@021bc000 {
				compatible = "fsl,imx6q-ocotp\0syscon";
				reg = <0x21bc000 0x4000>;
				clocks = <0x02 0x80>;
				linux,phandle = <0x1c>;
				phandle = <0x1c>;
			};

			tzasc@021d0000 {
				reg = <0x21d0000 0x4000>;
				interrupts = <0x00 0x6c 0x04>;
			};

			tzasc@021d4000 {
				reg = <0x21d4000 0x4000>;
				interrupts = <0x00 0x6d 0x04>;
			};

			audmux@021d8000 {
				compatible = "fsl,imx6q-audmux\0fsl,imx31-audmux";
				reg = <0x21d8000 0x4000>;
				status = "okay";
				pinctrl-names = "default";
				pinctrl-0 = <0x3f>;
			};

			mipi@021dc000 {
				compatible = "fsl,imx6-mipi-csi2\0snps,dw-mipi-csi2";
				reg = <0x21dc000 0x4000>;
				#address-cells = <0x01>;
				#size-cells = <0x00>;
				interrupts = <0x00 0x64 0x04 0x00 0x65 0x04>;
				clocks = <0x02 0x8a 0x02 0xee 0x02 0x61>;
				clock-names = "dphy\0ref\0pix";
				status = "okay";

				port@1 {
					reg = <0x01>;

					endpoint {
						remote-endpoint = <0x40>;
						linux,phandle = <0x1f>;
						phandle = <0x1f>;
					};
				};

				port@2 {
					reg = <0x02>;

					endpoint {
						remote-endpoint = <0x41>;
						linux,phandle = <0x4d>;
						phandle = <0x4d>;
					};
				};

				port@3 {
					reg = <0x03>;

					endpoint {
						remote-endpoint = <0x42>;
						linux,phandle = <0x56>;
						phandle = <0x56>;
					};
				};

				port@4 {
					reg = <0x04>;

					endpoint {
						remote-endpoint = <0x43>;
						linux,phandle = <0x21>;
						phandle = <0x21>;
					};
				};

				port@0 {
					reg = <0x00>;

					endpoint {
						remote-endpoint = <0x44>;
						clock-lanes = <0x00>;
						data-lanes = <0x01 0x02>;
						linux,phandle = <0x77>;
						phandle = <0x77>;
					};
				};
			};

			mipi@021e0000 {
				#address-cells = <0x01>;
				#size-cells = <0x00>;
				reg = <0x21e0000 0x4000>;
				status = "disabled";

				ports {
					#address-cells = <0x01>;
					#size-cells = <0x00>;

					port@0 {
						reg = <0x00>;

						endpoint {
							remote-endpoint = <0x45>;
							linux,phandle = <0x4f>;
							phandle = <0x4f>;
						};
					};

					port@1 {
						reg = <0x01>;

						endpoint {
							remote-endpoint = <0x46>;
							linux,phandle = <0x53>;
							phandle = <0x53>;
						};
					};

					port@2 {
						reg = <0x02>;

						endpoint {
							remote-endpoint = <0x47>;
							linux,phandle = <0x59>;
							phandle = <0x59>;
						};
					};

					port@3 {
						reg = <0x03>;

						endpoint {
							remote-endpoint = <0x48>;
							linux,phandle = <0x5d>;
							phandle = <0x5d>;
						};
					};
				};
			};

			vdoa@021e4000 {
				compatible = "fsl,imx6q-vdoa";
				reg = <0x21e4000 0x4000>;
				interrupts = <0x00 0x12 0x04>;
				clocks = <0x02 0xca>;
			};

			serial@021e8000 {
				compatible = "fsl,imx6q-uart\0fsl,imx21-uart";
				reg = <0x21e8000 0x4000>;
				interrupts = <0x00 0x1b 0x04>;
				clocks = <0x02 0xa0 0x02 0xa1>;
				clock-names = "ipg\0per";
				dmas = <0x0f 0x1b 0x04 0x00 0x0f 0x1c 0x04 0x00>;
				dma-names = "rx\0tx";
				status = "okay";
				pinctrl-names = "default";
				pinctrl-0 = <0x49>;
			};

			serial@021ec000 {
				compatible = "fsl,imx6q-uart\0fsl,imx21-uart";
				reg = <0x21ec000 0x4000>;
				interrupts = <0x00 0x1c 0x04>;
				clocks = <0x02 0xa0 0x02 0xa1>;
				clock-names = "ipg\0per";
				dmas = <0x0f 0x1d 0x04 0x00 0x0f 0x1e 0x04 0x00>;
				dma-names = "rx\0tx";
				status = "disabled";
			};

			serial@021f0000 {
				compatible = "fsl,imx6q-uart\0fsl,imx21-uart";
				reg = <0x21f0000 0x4000>;
				interrupts = <0x00 0x1d 0x04>;
				clocks = <0x02 0xa0 0x02 0xa1>;
				clock-names = "ipg\0per";
				dmas = <0x0f 0x1f 0x04 0x00 0x0f 0x20 0x04 0x00>;
				dma-names = "rx\0tx";
				status = "okay";
				pinctrl-names = "default";
				pinctrl-0 = <0x4a>;
				fsl,uart-has-rtscts;
			};

			serial@021f4000 {
				compatible = "fsl,imx6q-uart\0fsl,imx21-uart";
				reg = <0x21f4000 0x4000>;
				interrupts = <0x00 0x1e 0x04>;
				clocks = <0x02 0xa0 0x02 0xa1>;
				clock-names = "ipg\0per";
				dmas = <0x0f 0x21 0x04 0x00 0x0f 0x22 0x04 0x00>;
				dma-names = "rx\0tx";
				status = "okay";
				pinctrl-names = "default";
				pinctrl-0 = <0x4b>;
			};
		};

		ipu@02400000 {
			#address-cells = <0x01>;
			#size-cells = <0x00>;
			compatible = "fsl,imx6q-ipu";
			reg = <0x2400000 0x400000>;
			interrupts = <0x00 0x06 0x04 0x00 0x05 0x04>;
			clocks = <0x02 0x82 0x02 0x83 0x02 0x84>;
			clock-names = "bus\0di0\0di1";
			resets = <0x13 0x02>;

			port@0 {
				reg = <0x00>;
				linux,phandle = <0x63>;
				phandle = <0x63>;

				endpoint {
					remote-endpoint = <0x4c>;
					linux,phandle = <0x20>;
					phandle = <0x20>;
				};
			};

			port@1 {
				reg = <0x01>;
				linux,phandle = <0x64>;
				phandle = <0x64>;

				endpoint {
					remote-endpoint = <0x4d>;
					linux,phandle = <0x41>;
					phandle = <0x41>;
				};
			};

			port@2 {
				#address-cells = <0x01>;
				#size-cells = <0x00>;
				reg = <0x02>;
				linux,phandle = <0x67>;
				phandle = <0x67>;

				disp0-endpoint {
				};

				hdmi-endpoint {
					remote-endpoint = <0x4e>;
					linux,phandle = <0x06>;
					phandle = <0x06>;
				};

				mipi-endpoint {
					remote-endpoint = <0x4f>;
					linux,phandle = <0x45>;
					phandle = <0x45>;
				};

				lvds0-endpoint {
					remote-endpoint = <0x50>;
					linux,phandle = <0x24>;
					phandle = <0x24>;
				};

				lvds1-endpoint {
					remote-endpoint = <0x51>;
					linux,phandle = <0x29>;
					phandle = <0x29>;
				};
			};

			port@3 {
				#address-cells = <0x01>;
				#size-cells = <0x00>;
				reg = <0x03>;
				linux,phandle = <0x68>;
				phandle = <0x68>;

				disp1-endpoint {
				};

				hdmi-endpoint {
					remote-endpoint = <0x52>;
					linux,phandle = <0x07>;
					phandle = <0x07>;
				};

				mipi-endpoint {
					remote-endpoint = <0x53>;
					linux,phandle = <0x46>;
					phandle = <0x46>;
				};

				lvds0-endpoint {
					remote-endpoint = <0x54>;
					linux,phandle = <0x25>;
					phandle = <0x25>;
				};

				lvds1-endpoint {
					remote-endpoint = <0x55>;
					linux,phandle = <0x2a>;
					phandle = <0x2a>;
				};
			};
		};

		sram@00900000 {
			compatible = "mmio-sram";
			reg = <0x900000 0x40000>;
			clocks = <0x02 0x8e>;
			linux,phandle = <0x14>;
			phandle = <0x14>;
		};

		sata@02200000 {
			compatible = "fsl,imx6q-ahci";
			reg = <0x2200000 0x4000>;
			interrupts = <0x00 0x27 0x04>;
			clocks = <0x02 0x9a 0x02 0xbb 0x02 0x69>;
			clock-names = "sata\0sata_ref\0ahb";
			status = "okay";
		};

		gpu@02204000 {
			compatible = "vivante,gc";
			reg = <0x2204000 0x4000>;
			interrupts = <0x00 0x0b 0x04>;
			clocks = <0x02 0x8f 0x02 0x79>;
			clock-names = "bus\0core";
			power-domains = <0x01 0x01>;
			linux,phandle = <0x6d>;
			phandle = <0x6d>;
		};

		ipu@02800000 {
			#address-cells = <0x01>;
			#size-cells = <0x00>;
			compatible = "fsl,imx6q-ipu";
			reg = <0x2800000 0x400000>;
			interrupts = <0x00 0x08 0x04 0x00 0x07 0x04>;
			clocks = <0x02 0x85 0x02 0x86 0x02 0x89>;
			clock-names = "bus\0di0\0di1";
			resets = <0x13 0x04>;

			port@0 {
				reg = <0x00>;
				linux,phandle = <0x65>;
				phandle = <0x65>;

				endpoint {
					remote-endpoint = <0x56>;
					linux,phandle = <0x42>;
					phandle = <0x42>;
				};
			};

			port@1 {
				reg = <0x01>;
				linux,phandle = <0x66>;
				phandle = <0x66>;

				endpoint {
					remote-endpoint = <0x57>;
					linux,phandle = <0x22>;
					phandle = <0x22>;
				};
			};

			port@2 {
				#address-cells = <0x01>;
				#size-cells = <0x00>;
				reg = <0x02>;
				linux,phandle = <0x69>;
				phandle = <0x69>;

				disp0-endpoint {
				};

				hdmi-endpoint {
					remote-endpoint = <0x58>;
					linux,phandle = <0x08>;
					phandle = <0x08>;
				};

				mipi-endpoint {
					remote-endpoint = <0x59>;
					linux,phandle = <0x47>;
					phandle = <0x47>;
				};

				lvds0-endpoint {
					remote-endpoint = <0x5a>;
					linux,phandle = <0x26>;
					phandle = <0x26>;
				};

				lvds1-endpoint {
					remote-endpoint = <0x5b>;
					linux,phandle = <0x2b>;
					phandle = <0x2b>;
				};
			};

			port@3 {
				#address-cells = <0x01>;
				#size-cells = <0x00>;
				reg = <0x03>;
				linux,phandle = <0x6a>;
				phandle = <0x6a>;

				hdmi-endpoint {
					remote-endpoint = <0x5c>;
					linux,phandle = <0x09>;
					phandle = <0x09>;
				};

				mipi-endpoint {
					remote-endpoint = <0x5d>;
					linux,phandle = <0x48>;
					phandle = <0x48>;
				};

				lvds0-endpoint {
					remote-endpoint = <0x5e>;
					linux,phandle = <0x27>;
					phandle = <0x27>;
				};

				lvds1-endpoint {
					remote-endpoint = <0x5f>;
					linux,phandle = <0x2c>;
					phandle = <0x2c>;
				};
			};
		};
	};

	cpus {
		#address-cells = <0x01>;
		#size-cells = <0x00>;

		cpu@0 {
			compatible = "arm,cortex-a9";
			device_type = "cpu";
			reg = <0x00>;
			next-level-cache = <0x60>;
			operating-points = <0x124f80 0x137478 0xf32a0 0x1312d0 0xd0020 0x1312d0 0xc15c0 0x11edd8 0x60ae0 0xee098>;
			fsl,soc-operating-points = <0x124f80 0x137478 0xf32a0 0x1312d0 0xd0020 0x1312d0 0xc15c0 0x11edd8 0x60ae0 0x11edd8>;
			clock-latency = <0xee6c>;
			clocks = <0x02 0x68 0x02 0x06 0x02 0x10 0x02 0x11 0x02 0xaa>;
			clock-names = "arm\0pll2_pfd2_396m\0step\0pll1_sw\0pll1_sys";
			arm-supply = <0x61>;
			pu-supply = <0x1e>;
			soc-supply = <0x62>;
		};

		cpu@1 {
			compatible = "arm,cortex-a9";
			device_type = "cpu";
			reg = <0x01>;
			next-level-cache = <0x60>;
		};

		cpu@2 {
			compatible = "arm,cortex-a9";
			device_type = "cpu";
			reg = <0x02>;
			next-level-cache = <0x60>;
		};

		cpu@3 {
			compatible = "arm,cortex-a9";
			device_type = "cpu";
			reg = <0x03>;
			next-level-cache = <0x60>;
		};
	};

	capture-subsystem {
		compatible = "fsl,imx-capture-subsystem";
		ports = <0x63 0x64 0x65 0x66>;
	};

	display-subsystem {
		compatible = "fsl,imx-display-subsystem";
		ports = <0x67 0x68 0x69 0x6a>;
		status = "okay";
	};

	gpu-subsystem {
		compatible = "fsl,imx-gpu-subsystem";
		cores = <0x6b 0x6c 0x6d>;
		status = "okay";
	};

	fb@0 {
		status = "okay";
		linux,phandle = <0x70>;
		phandle = <0x70>;
	};

	fb@1 {
		status = "okay";
		default_bpp = <0x18>;
		disp_dev = "hdmi";
		mode_str = "1920x1080M@60";
		interface_pix_fmt = "RGB24";
	};

	backlight {
		compatible = "pwm-backlight";
		pinctrl-names = "default";
		pinctrl-0 = <0x6e>;
		pwms = <0x6f 0x00 0x4c4b40>;
		brightness-levels = <0x00 0x01 0x02 0x03 0x04 0x05 0x06 0x07 0x08 0x09 0x0a 0x0b 0x0c 0x0d 0x0e 0x0f 0x10 0x11 0x12 0x13 0x14 0x15 0x16 0x17 0x18 0x19 0x1a 0x1b 0x1c 0x1d 0x1e 0x1f 0x20 0x21 0x22 0x23 0x24 0x25 0x26 0x27 0x28 0x29 0x2a 0x2b 0x2c 0x2d 0x2e 0x2f 0x30 0x31 0x32 0x33 0x34 0x35 0x36 0x37 0x38 0x39 0x3a 0x3b 0x3c 0x3d 0x3e 0x3f 0x40 0x41 0x42 0x43 0x44 0x45 0x46 0x47 0x48 0x49 0x4a 0x4b 0x4c 0x4d 0x4e 0x4f 0x50 0x51 0x52 0x53 0x54 0x55 0x56 0x57 0x58 0x59 0x5a 0x5b 0x5c 0x5d 0x5e 0x5f 0x60 0x61 0x62 0x63 0x64>;
		default-brightness-level = <0x50>;
		enable-gpios = <0x35 0x10 0x00>;
		fb = <0x70>;
		power-supply = <0x71>;
	};

	lcdpower {
		compatible = "gpio-backlight";
		pinctrl-names = "default";
		pinctrl-0 = <0x72>;
		gpios = <0x35 0x11 0x00>;
		default-on;
		fb = <0x70>;
	};

	i2c-gpio-0 {
		compatible = "i2c-gpio";
		pinctrl-names = "default";
		pinctrl-0 = <0x73>;
		gpios = <0x35 0x1c 0x00 0x35 0x1e 0x00>;
		#address-cells = <0x01>;
		#size-cells = <0x00>;
		i2c-gpio,delay-us = <0x02>;

		pfuze100@08 {
			compatible = "fsl,pfuze100";
			reg = <0x08>;
			interrupt-parent = <0x74>;
			interrupts = <0x0d 0x08>;

			regulators {

				vsnvs {
					regulator-min-microvolt = <0xf4240>;
					regulator-max-microvolt = <0x2dc6c0>;
					regulator-boot-on;
					regulator-always-on;
				};

				sw1ab {
					regulator-name = "V_CORE_S0";
					regulator-min-microvolt = <0x493e0>;
					regulator-max-microvolt = <0x1c9c38>;
					regulator-boot-on;
					regulator-always-on;
				};

				sw1c {
					regulator-name = "V_VDDSOC_S0";
					regulator-min-microvolt = <0x493e0>;
					regulator-max-microvolt = <0x1c9c38>;
					regulator-boot-on;
					regulator-always-on;
				};

				sw2 {
					regulator-name = "V_3V15_S0";
					regulator-min-microvolt = "\0\f5";
					regulator-max-microvolt = <0x325aa0>;
					regulator-boot-on;
					regulator-always-on;
				};

				sw3a {
					regulator-min-microvolt = <0x61a80>;
					regulator-max-microvolt = <0x1e22d8>;
					regulator-boot-on;
					regulator-always-on;
				};

				sw3b {
					regulator-min-microvolt = <0x61a80>;
					regulator-max-microvolt = <0x1e22d8>;
					regulator-boot-on;
					regulator-always-on;
				};

				sw4 {
					regulator-name = "V_1V8_S0";
					regulator-min-microvolt = "\0\f5";
					regulator-max-microvolt = <0x325aa0>;
					regulator-boot-on;
					regulator-always-on;
				};

				swbst {
					regulator-name = "V_5V0_S0";
					regulator-min-microvolt = <0x4c4b40>;
					regulator-max-microvolt = <0x4e9530>;
					regulator-always-on;
				};

				vrefddr {
					regulator-boot-on;
					regulator-always-on;
				};

				vgen1 {
					regulator-min-microvolt = "\0\f5";
					regulator-max-microvolt = <0x17a6b0>;
				};

				vgen2 {
					regulator-min-microvolt = "\0\f5";
					regulator-max-microvolt = <0x17a6b0>;
				};

				vgen3 {
					regulator-min-microvolt = <0x1b7740>;
					regulator-max-microvolt = <0x325aa0>;
				};

				vgen4 {
					regulator-min-microvolt = <0x1b7740>;
					regulator-max-microvolt = <0x325aa0>;
				};

				vgen5 {
					regulator-name = "V_2V5_S0";
					regulator-min-microvolt = <0x1b7740>;
					regulator-max-microvolt = <0x325aa0>;
				};

				vgen6 {
					regulator-min-microvolt = <0x1b7740>;
					regulator-max-microvolt = <0x325aa0>;
				};
			};
		};
	};

	i2c-gpio-1 {
		compatible = "i2c-gpio";
		pinctrl-names = "default";
		pinctrl-0 = <0x75>;
		gpios = <0x76 0x0a 0x00 0x35 0x06 0x00>;
		#address-cells = <0x01>;
		#size-cells = <0x00>;
		i2c-gpio,delay-us = <0x02>;

		ov5640@3c {
			compatible = "ovti,ov5640";
			reg = <0x3c>;
			clocks = <0x02 0xc8>;
			clock-names = "xclk";
			powerdown-gpios = <0x0d 0x00 0x00>;
			reset-gpios = <0x0d 0x02 0x01>;

			port {
				#address-cells = <0x01>;
				#size-cells = <0x00>;

				endpoint {
					remote-endpoint = <0x77>;
					clock-lanes = <0x00>;
					data-lanes = <0x01 0x02>;
					linux,phandle = <0x44>;
					phandle = <0x44>;
				};
			};
		};
	};

	i2c-gpio-2 {
		compatible = "i2c-gpio";
		pinctrl-names = "default";
		pinctrl-0 = <0x78>;
		gpios = <0x35 0x15 0x00 0x35 0x13 0x00>;
		#address-cells = <0x01>;
		#size-cells = <0x00>;
		i2c-gpio,delay-us = <0x02>;
	};

	regulators {
		compatible = "simple-bus";
		#address-cells = <0x01>;
		#size-cells = <0x00>;

		regulator@0 {
			compatible = "regulator-fixed";
			reg = <0x00>;
			regulator-name = "V_3V3_S5";
			regulator-min-microvolt = <0x325aa0>;
			regulator-max-microvolt = <0x325aa0>;
			regulator-boot-on;
			regulator-always-on;
		};

		regulator@1 {
			compatible = "regulator-fixed";
			reg = <0x01>;
			regulator-name = "V_1V8_S5";
			regulator-min-microvolt = <0x1b7740>;
			regulator-max-microvolt = <0x1b7740>;
			regulator-boot-on;
			regulator-always-on;
		};

		regulator@2 {
			compatible = "regulator-fixed";
			reg = <0x02>;
			regulator-name = "V_3V3_S0";
			regulator-min-microvolt = <0x325aa0>;
			regulator-max-microvolt = <0x325aa0>;
			regulator-boot-on;
			regulator-always-on;
			linux,phandle = <0x32>;
			phandle = <0x32>;
		};

		regulator@3 {
			compatible = "regulator-fixed";
			reg = <0x03>;
			regulator-name = "V_1V0_S0";
			regulator-min-microvolt = <0xf4240>;
			regulator-max-microvolt = <0xf4240>;
			regulator-boot-on;
			regulator-always-on;
		};

		regulator@100 {
			compatible = "regulator-fixed";
			reg = <0x64>;
			regulator-name = "V_31V9_BKLT";
			regulator-min-microvolt = <0xb71b00>;
			regulator-max-microvolt = <0xb71b00>;
			regulator-boot-on;
			regulator-always-on;
			linux,phandle = <0x71>;
			phandle = <0x71>;
		};

		regulator@101 {
			compatible = "regulator-fixed";
			reg = <0x65>;
			regulator-name = "V_3V3_SDCARD";
			regulator-min-microvolt = <0x325aa0>;
			regulator-max-microvolt = <0x325aa0>;
			gpio = <0x35 0x1d 0x00>;
			enable-active-high;
			linux,phandle = <0x37>;
			phandle = <0x37>;
		};

		regulator@102 {
			compatible = "regulator-fixed";
			reg = <0x66>;
			regulator-name = "CAN0_EN";
			regulator-min-microvolt = <0x325aa0>;
			regulator-max-microvolt = <0x325aa0>;
			gpio = <0x79 0x06 0x00>;
			enable-active-high;
			linux,phandle = <0x17>;
			phandle = <0x17>;
		};

		regulator@103 {
			compatible = "regulator-fixed";
			reg = <0x67>;
			regulator-name = "CAN1_EN";
			regulator-min-microvolt = <0x325aa0>;
			regulator-max-microvolt = <0x325aa0>;
			gpio = <0x79 0x07 0x00>;
			enable-active-high;
			linux,phandle = <0x19>;
			phandle = <0x19>;
		};

		regulator@104 {
			compatible = "regulator-fixed";
			reg = <0x68>;
			regulator-name = "V_3V3";
			regulator-min-microvolt = <0x325aa0>;
			regulator-max-microvolt = <0x325aa0>;
			regulator-boot-on;
			regulator-always-on;
			linux,phandle = <0x3a>;
			phandle = <0x3a>;
		};

		regulator@105 {
			compatible = "regulator-fixed";
			reg = <0x69>;
			regulator-name = "V_IO_1V8";
			regulator-min-microvolt = <0x1b7740>;
			regulator-max-microvolt = <0x1b7740>;
			regulator-boot-on;
			regulator-always-on;
			linux,phandle = <0x3b>;
			phandle = <0x3b>;
		};

		regulator@106 {
			compatible = "regulator-fixed";
			reg = <0x6a>;
			regulator-name = "V_1V8_LDO";
			regulator-min-microvolt = <0x1b7740>;
			regulator-max-microvolt = <0x1b7740>;
			regulator-boot-on;
			regulator-always-on;
			linux,phandle = <0x3e>;
			phandle = <0x3e>;
		};

		regulator@107 {
			compatible = "regulator-fixed";
			reg = <0x6b>;
			regulator-name = "USB_OTG_VBUS";
			regulator-min-microvolt = <0x4c4b40>;
			regulator-max-microvolt = <0x4c4b40>;
			gpio = <0x7a 0x12 0x00>;
			enable-active-high;
			linux,phandle = <0x30>;
			phandle = <0x30>;
		};
	};

    watchdog {
		compatible = "linux,wdt-gpio";
		gpios = <0x0d 0x02 0x01>;
		hw_algo = "toggle";
        always-running = <1>;
		hw_margin_ms = <2123>;
	};

	gpio-keys {
		compatible = "gpio-keys";
		pinctrl-names = "default";
		pinctrl-0 = <0x7b>;

		power {
			label = "Power";
			gpios = <0x0b 0x10 0x01>;
			linux,code = <0x74>;
			gpio-key,wakeup;
			debounce-interval = <0x01>;
		};

		sleep {
			label = "Sleep";
			gpios = <0x0b 0x11 0x01>;
			linux,code = <0x8e>;
			gpio-key,wakeup;
			debounce-interval = <0x01>;
		};

		lid {
			label = "Lid";
			gpios = <0x7a 0x00 0x01>;
			linux,input-type = <0x05>;
			linux,code = <0x00>;
			gpio-key,wakeup;
			debounce-interval = <0x01>;
		};
	};

	v4l2_out {
		compatible = "fsl,mxc_v4l2_output";
		status = "okay";
	};

	/*ssi1_audio {
		ssi-controller = <0x7c>;
		mux-int-port = <0x01>;
		mux-ext-port = <0x03>;
		compatible = "fsl,imx-audio-wm8903";
		model = "imx-wm8903";
		audio-codec = <0x7d>;
		audio-routing = "Headphone Jack\0HPOUTR\0Headphone Jack\0HPOUTL\0Mic Jack\0MICBIAS\0IN1L\0Mic Jack";
	};
    */

};
